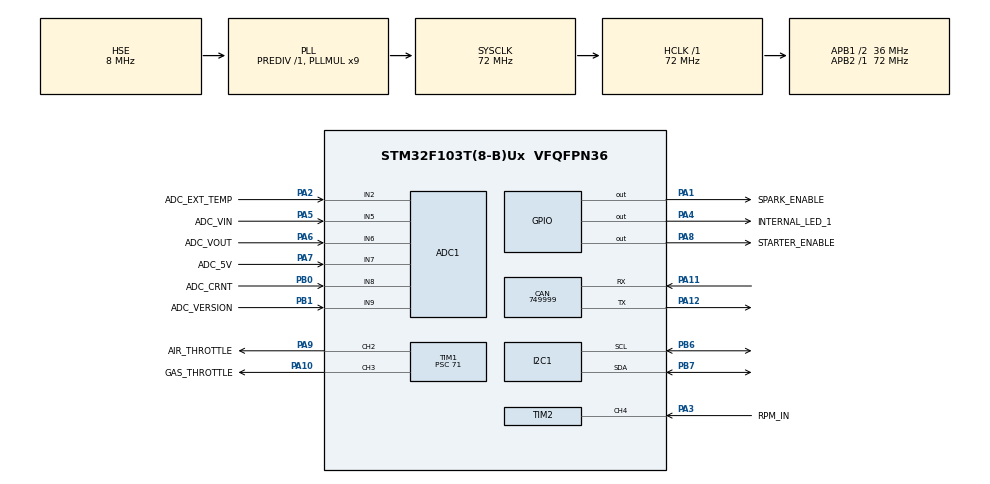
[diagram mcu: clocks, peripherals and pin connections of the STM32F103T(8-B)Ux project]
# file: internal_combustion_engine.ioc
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ADC1.Channel-0\#ChannelRegularConversion=ADC_CHANNEL_2
ADC1.Channel-3\#ChannelRegularConversion=ADC_CHANNEL_5
ADC1.Channel-4\#ChannelRegularConversion=ADC_CHANNEL_7
ADC1.Channel-5\#ChannelRegularConversion=ADC_CHANNEL_8
ADC1.Channel-6\#ChannelRegularConversion=ADC_CHANNEL_6
ADC1.Channel-7\#ChannelRegularConversion=ADC_CHANNEL_TEMPSENSOR
ADC1.Channel-8\#ChannelRegularConversion=ADC_CHANNEL_9
ADC1.EnableInjectedConversion=DISABLE
ADC1.InjNumberOfConversion=2
ADC1.NbrOfConversion=7
ADC1.NbrOfConversionFlag=1
ADC1.Rank-0\#ChannelRegularConversion=1
ADC1.Rank-3\#ChannelRegularConversion=2
ADC1.Rank-4\#ChannelRegularConversion=3
ADC1.Rank-5\#ChannelRegularConversion=4
ADC1.Rank-6\#ChannelRegularConversion=5
ADC1.Rank-7\#ChannelRegularConversion=6
ADC1.Rank-8\#ChannelRegularConversion=7
ADC1.SamplingTime-0\#ChannelRegularConversion=ADC_SAMPLETIME_55CYCLES_5
ADC1.SamplingTime-3\#ChannelRegularConversion=ADC_SAMPLETIME_55CYCLES_5
ADC1.SamplingTime-4\#ChannelRegularConversion=ADC_SAMPLETIME_55CYCLES_5
ADC1.SamplingTime-5\#ChannelRegularConversion=ADC_SAMPLETIME_55CYCLES_5
ADC1.SamplingTime-6\#ChannelRegularConversion=ADC_SAMPLETIME_55CYCLES_5
ADC1.SamplingTime-7\#ChannelRegularConversion=ADC_SAMPLETIME_55CYCLES_5
ADC1.SamplingTime-8\#ChannelRegularConversion=ADC_SAMPLETIME_55CYCLES_5
ADC1.master=1
CAN.BS1=CAN_BS1_1TQ
CAN.BS2=CAN_BS2_1TQ
CAN.CalculateBaudRate=749999
CAN.CalculateTimeBit=1333
CAN.CalculateTimeQuantum=444.44444444444446
Dma.ADC1.0.Direction=DMA_PERIPH_TO_MEMORY
Dma.ADC1.0.Instance=DMA1_Channel1
Dma.ADC1.0.MemDataAlignment=DMA_MDATAALIGN_HALFWORD
Dma.ADC1.0.MemInc=DMA_MINC_ENABLE
Dma.ADC1.0.Mode=DMA_CIRCULAR
Dma.ADC1.0.PeriphDataAlignment=DMA_PDATAALIGN_HALFWORD
Dma.ADC1.0.PeriphInc=DMA_PINC_DISABLE
Dma.ADC1.0.Priority=DMA_PRIORITY_LOW
Dma.Request0=ADC1
Mcu.Family=STM32F1
Mcu.Name=STM32F103T(8-B)Ux
Mcu.Package=VFQFPN36
NVIC.DMA1_Channel1_IRQn=true\:0\:0\:false\:false\:true\:false\:true\:true
NVIC.PriorityGroup=NVIC_PRIORITYGROUP_4
NVIC.TIM2_IRQn=true\:0\:0\:false\:false\:true\:true\:true\:true
NVIC.TIM3_IRQn=true\:15\:0\:false\:false\:true\:false\:true\:true
NVIC.TimeBase=TIM3_IRQn
NVIC.TimeBaseIP=TIM3
PA1.GPIO_Label=SPARK_ENABLE
PA1.Signal=GPIO_Output
PA10.GPIO_Label=GAS_THROTTLE
PA10.Signal=S_TIM1_CH3
PA11.Mode=CAN_Activate
PA11.Signal=CAN_RX
PA12.Mode=CAN_Activate
PA12.Signal=CAN_TX
PA13.Mode=Serial_Wire
PA13.Signal=SYS_JTMS-SWDIO
PA14.Mode=Serial_Wire
PA14.Signal=SYS_JTCK-SWCLK
PA2.GPIO_Label=ADC_EXT_TEMP
PA2.Signal=ADCx_IN2
PA3.GPIO_Label=RPM_IN
PA3.Signal=S_TIM2_CH4
PA4.GPIO_Label=INTERNAL_LED_1
PA4.Signal=GPIO_Output
PA5.GPIO_Label=ADC_VIN
PA5.Signal=ADCx_IN5
PA6.GPIO_Label=ADC_VOUT
PA6.Signal=ADCx_IN6
PA7.GPIO_Label=ADC_5V
PA7.Signal=ADCx_IN7
PA8.GPIO_Label=STARTER_ENABLE
PA8.GPIO_ModeDefaultOutputPP=GPIO_MODE_OUTPUT_OD
PA8.GPIO_PuPd=GPIO_NOPULL
PA8.Signal=GPIO_Output
PA9.GPIO_Label=AIR_THROTTLE
PA9.Signal=S_TIM1_CH2
PB0.GPIO_Label=ADC_CRNT
PB0.Signal=ADCx_IN8
PB1.GPIO_Label=ADC_VERSION
PB1.Signal=ADCx_IN9
PB6.Mode=I2C
PB6.Signal=I2C1_SCL
PB7.Mode=I2C
PB7.Signal=I2C1_SDA
PD0-OSC_IN.Mode=HSE-External-Oscillator
PD0-OSC_IN.Signal=RCC_OSC_IN
PD1-OSC_OUT.Mode=HSE-External-Oscillator
PD1-OSC_OUT.Signal=RCC_OSC_OUT
ProjectManager.HeapSize=0x200
ProjectManager.StackSize=0x400
ProjectManager.TargetToolchain=Makefile
RCC.ADCPresc=RCC_ADCPCLK2_DIV6
RCC.AHBFreq_Value=72000000
RCC.APB1CLKDivider=RCC_HCLK_DIV2
RCC.APB1Freq_Value=36000000
RCC.APB1TimFreq_Value=72000000
RCC.APB2Freq_Value=72000000
RCC.APB2TimFreq_Value=72000000
RCC.HCLKFreq_Value=72000000
RCC.PLLMUL=RCC_PLL_MUL9
RCC.PLLSourceVirtual=RCC_PLLSOURCE_HSE
RCC.SYSCLKFreq_VALUE=72000000
RCC.SYSCLKSource=RCC_SYSCLKSOURCE_PLLCLK
RCC.USBFreq_Value=72000000
SH.ADCx_IN2.0=ADC1_IN2,IN2
SH.ADCx_IN5.0=ADC1_IN5,IN5
SH.ADCx_IN6.0=ADC1_IN6,IN6
SH.ADCx_IN7.0=ADC1_IN7,IN7
SH.ADCx_IN8.0=ADC1_IN8,IN8
SH.ADCx_IN9.0=ADC1_IN9,IN9
SH.S_TIM1_CH2.0=TIM1_CH2,PWM Generation2 CH2
SH.S_TIM1_CH3.0=TIM1_CH3,PWM Generation3 CH3
SH.S_TIM2_CH4.0=TIM2_CH4,Input_Capture4_from_TI4
TIM1.Channel-PWM\ Generation2\ CH2=TIM_CHANNEL_2
TIM1.Channel-PWM\ Generation3\ CH3=TIM_CHANNEL_3
TIM1.Period=20000
TIM1.Prescaler=71
TIM2.Channel-Input_Capture4_from_TI4=TIM_CHANNEL_4
TIM2.Period=50000
TIM2.Prescaler=719
VP_ADC1_TempSens_Input.Mode=IN-TempSens
VP_SYS_VS_tim3.Mode=TIM3
VP_TIM1_VS_ClockSourceINT.Mode=Internal
VP_TIM2_VS_ClockSourceINT.Mode=Internal
board=custom

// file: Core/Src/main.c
/* USER CODE BEGIN Header */
/**
  ******************************************************************************
  * @file           : main.c
  * @brief          : Main program body
  ******************************************************************************
  * @attention
  *
  * Copyright (c) 2023 STMicroelectronics.
  * All rights reserved.
  *
  * This software is licensed under terms that can be found in the LICENSE file
  * in the root directory of this software component.
  * If no LICENSE file comes with this software, it is provided AS-IS.
  *
  ******************************************************************************
  */
/* USER CODE END Header */
#include "main.h"

/* USER CODE BEGIN Includes */
#include "application.hpp"
/* USER CODE END Includes */

ADC_HandleTypeDef hadc1;
DMA_HandleTypeDef hdma_adc1;

CAN_HandleTypeDef hcan;

I2C_HandleTypeDef hi2c1;

TIM_HandleTypeDef htim1;
TIM_HandleTypeDef htim2;

void SystemClock_Config(void);
static void MX_GPIO_Init(void);
static void MX_DMA_Init(void);
static void MX_CAN_Init(void);
static void MX_TIM2_Init(void);
static void MX_ADC1_Init(void);
static void MX_TIM1_Init(void);
static void MX_I2C1_Init(void);

int main(void)
{

  /* MCU Configuration--------------------------------------------------------*/

  /* Reset of all peripherals, Initializes the Flash interface and the Systick. */
  HAL_Init();

  /* Configure the system clock */
  SystemClock_Config();

  /* Initialize all configured peripherals */
  MX_GPIO_Init();
  MX_DMA_Init();
  MX_CAN_Init();
  MX_TIM2_Init();
  MX_ADC1_Init();
  MX_TIM1_Init();
  MX_I2C1_Init();
  /* USER CODE BEGIN 2 */
  application_entry_point();
  /* USER CODE END 2 */

  /* Infinite loop */
  while (1)
  {

  }
}

void SystemClock_Config(void)
{
  RCC_OscInitTypeDef RCC_OscInitStruct = {0};
  RCC_ClkInitTypeDef RCC_ClkInitStruct = {0};
  RCC_PeriphCLKInitTypeDef PeriphClkInit = {0};

  /** Initializes the RCC Oscillators according to the specified parameters
  * in the RCC_OscInitTypeDef structure.
  */
  RCC_OscInitStruct.OscillatorType = RCC_OSCILLATORTYPE_HSE;
  RCC_OscInitStruct.HSEState = RCC_HSE_ON;
  RCC_OscInitStruct.HSEPredivValue = RCC_HSE_PREDIV_DIV1;
  RCC_OscInitStruct.HSIState = RCC_HSI_ON;
  RCC_OscInitStruct.PLL.PLLState = RCC_PLL_ON;
  RCC_OscInitStruct.PLL.PLLSource = RCC_PLLSOURCE_HSE;
  RCC_OscInitStruct.PLL.PLLMUL = RCC_PLL_MUL9;
  if (HAL_RCC_OscConfig(&RCC_OscInitStruct) != HAL_OK)
  {
    Error_Handler();
  }

  /** Initializes the CPU, AHB and APB buses clocks
  */
  RCC_ClkInitStruct.ClockType = RCC_CLOCKTYPE_HCLK|RCC_CLOCKTYPE_SYSCLK
                              |RCC_CLOCKTYPE_PCLK1|RCC_CLOCKTYPE_PCLK2;
  RCC_ClkInitStruct.SYSCLKSource = RCC_SYSCLKSOURCE_PLLCLK;
  RCC_ClkInitStruct.AHBCLKDivider = RCC_SYSCLK_DIV1;
  RCC_ClkInitStruct.APB1CLKDivider = RCC_HCLK_DIV2;
  RCC_ClkInitStruct.APB2CLKDivider = RCC_HCLK_DIV1;

  if (HAL_RCC_ClockConfig(&RCC_ClkInitStruct, FLASH_LATENCY_2) != HAL_OK)
  {
    Error_Handler();
  }
  PeriphClkInit.PeriphClockSelection = RCC_PERIPHCLK_ADC;
  PeriphClkInit.AdcClockSelection = RCC_ADCPCLK2_DIV6;
  if (HAL_RCCEx_PeriphCLKConfig(&PeriphClkInit) != HAL_OK)
  {
    Error_Handler();
  }
}

static void MX_ADC1_Init(void)
{

  ADC_ChannelConfTypeDef sConfig = {0};

  /** Common config
  */
  hadc1.Instance = ADC1;
  hadc1.Init.ScanConvMode = ADC_SCAN_ENABLE;
  hadc1.Init.ContinuousConvMode = DISABLE;
  hadc1.Init.DiscontinuousConvMode = DISABLE;
  hadc1.Init.ExternalTrigConv = ADC_SOFTWARE_START;
  hadc1.Init.DataAlign = ADC_DATAALIGN_RIGHT;
  hadc1.Init.NbrOfConversion = 7;
  if (HAL_ADC_Init(&hadc1) != HAL_OK)
  {
    Error_Handler();
  }

  /** Configure Regular Channel
  */
  sConfig.Channel = ADC_CHANNEL_2;
  sConfig.Rank = ADC_REGULAR_RANK_1;
  sConfig.SamplingTime = ADC_SAMPLETIME_55CYCLES_5;
  if (HAL_ADC_ConfigChannel(&hadc1, &sConfig) != HAL_OK)
  {
    Error_Handler();
  }

  /** Configure Regular Channel
  */
  sConfig.Channel = ADC_CHANNEL_5;
  sConfig.Rank = ADC_REGULAR_RANK_2;
  if (HAL_ADC_ConfigChannel(&hadc1, &sConfig) != HAL_OK)
  {
    Error_Handler();
  }

  /** Configure Regular Channel
  */
  sConfig.Channel = ADC_CHANNEL_7;
  sConfig.Rank = ADC_REGULAR_RANK_3;
  if (HAL_ADC_ConfigChannel(&hadc1, &sConfig) != HAL_OK)
  {
    Error_Handler();
  }

  /** Configure Regular Channel
  */
  sConfig.Channel = ADC_CHANNEL_8;
  sConfig.Rank = ADC_REGULAR_RANK_4;
  if (HAL_ADC_ConfigChannel(&hadc1, &sConfig) != HAL_OK)
  {
    Error_Handler();
  }

  /** Configure Regular Channel
  */
  sConfig.Channel = ADC_CHANNEL_6;
  sConfig.Rank = ADC_REGULAR_RANK_5;
  if (HAL_ADC_ConfigChannel(&hadc1, &sConfig) != HAL_OK)
  {
    Error_Handler();
  }

  /** Configure Regular Channel
  */
  sConfig.Channel = ADC_CHANNEL_TEMPSENSOR;
  sConfig.Rank = ADC_REGULAR_RANK_6;
  if (HAL_ADC_ConfigChannel(&hadc1, &sConfig) != HAL_OK)
  {
    Error_Handler();
  }

  /** Configure Regular Channel
  */
  sConfig.Channel = ADC_CHANNEL_9;
  sConfig.Rank = ADC_REGULAR_RANK_7;
  if (HAL_ADC_ConfigChannel(&hadc1, &sConfig) != HAL_OK)
  {
    Error_Handler();
  }

}

static void MX_CAN_Init(void)
{

  hcan.Instance = CAN1;
  hcan.Init.Prescaler = 16;
  hcan.Init.Mode = CAN_MODE_NORMAL;
  hcan.Init.SyncJumpWidth = CAN_SJW_1TQ;
  hcan.Init.TimeSeg1 = CAN_BS1_1TQ;
  hcan.Init.TimeSeg2 = CAN_BS2_1TQ;
  hcan.Init.TimeTriggeredMode = DISABLE;
  hcan.Init.AutoBusOff = DISABLE;
  hcan.Init.AutoWakeUp = DISABLE;
  hcan.Init.AutoRetransmission = DISABLE;
  hcan.Init.ReceiveFifoLocked = DISABLE;
  hcan.Init.TransmitFifoPriority = DISABLE;
  if (HAL_CAN_Init(&hcan) != HAL_OK)
  {
    Error_Handler();
  }

}

static void MX_I2C1_Init(void)
{

  hi2c1.Instance = I2C1;
  hi2c1.Init.ClockSpeed = 100000;
  hi2c1.Init.DutyCycle = I2C_DUTYCYCLE_2;
  hi2c1.Init.OwnAddress1 = 0;
  hi2c1.Init.AddressingMode = I2C_ADDRESSINGMODE_7BIT;
  hi2c1.Init.DualAddressMode = I2C_DUALADDRESS_DISABLE;
  hi2c1.Init.OwnAddress2 = 0;
  hi2c1.Init.GeneralCallMode = I2C_GENERALCALL_DISABLE;
  hi2c1.Init.NoStretchMode = I2C_NOSTRETCH_DISABLE;
  if (HAL_I2C_Init(&hi2c1) != HAL_OK)
  {
    Error_Handler();
  }

}

static void MX_TIM1_Init(void)
{

  TIM_ClockConfigTypeDef sClockSourceConfig = {0};
  TIM_MasterConfigTypeDef sMasterConfig = {0};
  TIM_OC_InitTypeDef sConfigOC = {0};
  TIM_BreakDeadTimeConfigTypeDef sBreakDeadTimeConfig = {0};

  htim1.Instance = TIM1;
  htim1.Init.Prescaler = 71;
  htim1.Init.CounterMode = TIM_COUNTERMODE_UP;
  htim1.Init.Period = 20000;
  htim1.Init.ClockDivision = TIM_CLOCKDIVISION_DIV1;
  htim1.Init.RepetitionCounter = 0;
  htim1.Init.AutoReloadPreload = TIM_AUTORELOAD_PRELOAD_DISABLE;
  if (HAL_TIM_Base_Init(&htim1) != HAL_OK)
  {
    Error_Handler();
  }
  sClockSourceConfig.ClockSource = TIM_CLOCKSOURCE_INTERNAL;
  if (HAL_TIM_ConfigClockSource(&htim1, &sClockSourceConfig) != HAL_OK)
  {
    Error_Handler();
  }
  if (HAL_TIM_PWM_Init(&htim1) != HAL_OK)
  {
    Error_Handler();
  }
  sMasterConfig.MasterOutputTrigger = TIM_TRGO_RESET;
  sMasterConfig.MasterSlaveMode = TIM_MASTERSLAVEMODE_DISABLE;
  if (HAL_TIMEx_MasterConfigSynchronization(&htim1, &sMasterConfig) != HAL_OK)
  {
    Error_Handler();
  }
  sConfigOC.OCMode = TIM_OCMODE_PWM1;
  sConfigOC.Pulse = 0;
  sConfigOC.OCPolarity = TIM_OCPOLARITY_HIGH;
  sConfigOC.OCNPolarity = TIM_OCNPOLARITY_HIGH;
  sConfigOC.OCFastMode = TIM_OCFAST_DISABLE;
  sConfigOC.OCIdleState = TIM_OCIDLESTATE_RESET;
  sConfigOC.OCNIdleState = TIM_OCNIDLESTATE_RESET;
  if (HAL_TIM_PWM_ConfigChannel(&htim1, &sConfigOC, TIM_CHANNEL_2) != HAL_OK)
  {
    Error_Handler();
  }
  if (HAL_TIM_PWM_ConfigChannel(&htim1, &sConfigOC, TIM_CHANNEL_3) != HAL_OK)
  {
    Error_Handler();
  }
  sBreakDeadTimeConfig.OffStateRunMode = TIM_OSSR_DISABLE;
  sBreakDeadTimeConfig.OffStateIDLEMode = TIM_OSSI_DISABLE;
  sBreakDeadTimeConfig.LockLevel = TIM_LOCKLEVEL_OFF;
  sBreakDeadTimeConfig.DeadTime = 0;
  sBreakDeadTimeConfig.BreakState = TIM_BREAK_DISABLE;
  sBreakDeadTimeConfig.BreakPolarity = TIM_BREAKPOLARITY_HIGH;
  sBreakDeadTimeConfig.AutomaticOutput = TIM_AUTOMATICOUTPUT_DISABLE;
  if (HAL_TIMEx_ConfigBreakDeadTime(&htim1, &sBreakDeadTimeConfig) != HAL_OK)
  {
    Error_Handler();
  }
  HAL_TIM_MspPostInit(&htim1);

}

static void MX_TIM2_Init(void)
{

  TIM_ClockConfigTypeDef sClockSourceConfig = {0};
  TIM_MasterConfigTypeDef sMasterConfig = {0};
  TIM_IC_InitTypeDef sConfigIC = {0};

  htim2.Instance = TIM2;
  htim2.Init.Prescaler = 719;
  htim2.Init.CounterMode = TIM_COUNTERMODE_UP;
  htim2.Init.Period = 50000;
  htim2.Init.ClockDivision = TIM_CLOCKDIVISION_DIV1;
  htim2.Init.AutoReloadPreload = TIM_AUTORELOAD_PRELOAD_DISABLE;
  if (HAL_TIM_Base_Init(&htim2) != HAL_OK)
  {
    Error_Handler();
  }
  sClockSourceConfig.ClockSource = TIM_CLOCKSOURCE_INTERNAL;
  if (HAL_TIM_ConfigClockSource(&htim2, &sClockSourceConfig) != HAL_OK)
  {
    Error_Handler();
  }
  if (HAL_TIM_IC_Init(&htim2) != HAL_OK)
  {
    Error_Handler();
  }
  sMasterConfig.MasterOutputTrigger = TIM_TRGO_RESET;
  sMasterConfig.MasterSlaveMode = TIM_MASTERSLAVEMODE_DISABLE;
  if (HAL_TIMEx_MasterConfigSynchronization(&htim2, &sMasterConfig) != HAL_OK)
  {
    Error_Handler();
  }
  sConfigIC.ICPolarity = TIM_INPUTCHANNELPOLARITY_RISING;
  sConfigIC.ICSelection = TIM_ICSELECTION_DIRECTTI;
  sConfigIC.ICPrescaler = TIM_ICPSC_DIV1;
  sConfigIC.ICFilter = 0;
  if (HAL_TIM_IC_ConfigChannel(&htim2, &sConfigIC, TIM_CHANNEL_4) != HAL_OK)
  {
    Error_Handler();
  }

}

static void MX_DMA_Init(void)
{

  /* DMA controller clock enable */
  __HAL_RCC_DMA1_CLK_ENABLE();

  /* DMA interrupt init */
  /* DMA1_Channel1_IRQn interrupt configuration */
  HAL_NVIC_SetPriority(DMA1_Channel1_IRQn, 0, 0);
  HAL_NVIC_EnableIRQ(DMA1_Channel1_IRQn);

}

static void MX_GPIO_Init(void)
{
  GPIO_InitTypeDef GPIO_InitStruct = {0};

  /* GPIO Ports Clock Enable */
  __HAL_RCC_GPIOD_CLK_ENABLE();
  __HAL_RCC_GPIOA_CLK_ENABLE();
  __HAL_RCC_GPIOB_CLK_ENABLE();

  /*Configure GPIO pin Output Level */
  HAL_GPIO_WritePin(GPIOA, SPARK_ENABLE_Pin|INTERNAL_LED_1_Pin|STARTER_ENABLE_Pin, GPIO_PIN_RESET);

  /*Configure GPIO pins : SPARK_ENABLE_Pin INTERNAL_LED_1_Pin */
  GPIO_InitStruct.Pin = SPARK_ENABLE_Pin|INTERNAL_LED_1_Pin;
  GPIO_InitStruct.Mode = GPIO_MODE_OUTPUT_PP;
  GPIO_InitStruct.Pull = GPIO_NOPULL;
  GPIO_InitStruct.Speed = GPIO_SPEED_FREQ_LOW;
  HAL_GPIO_Init(GPIOA, &GPIO_InitStruct);

  /*Configure GPIO pin : STARTER_ENABLE_Pin */
  GPIO_InitStruct.Pin = STARTER_ENABLE_Pin;
  GPIO_InitStruct.Mode = GPIO_MODE_OUTPUT_OD;
  GPIO_InitStruct.Pull = GPIO_NOPULL;
  GPIO_InitStruct.Speed = GPIO_SPEED_FREQ_LOW;
  HAL_GPIO_Init(STARTER_ENABLE_GPIO_Port, &GPIO_InitStruct);

}

void HAL_TIM_PeriodElapsedCallback(TIM_HandleTypeDef *htim)
{
  if (htim->Instance == TIM3) {
    HAL_IncTick();
  }
}

void Error_Handler(void)
{
  __disable_irq();
  while (1)
  {
  }
}
